# MLDR187 register map
File version: 1.4
MLDR187. Rev2+
CPU: MDR32F02, little endian
Registers are 32-bit, read-write, no defined reset value unless marked. A register's access mark holds for its fields unless they carry their own. Offsets are from the block's base; lines under a group give offsets from that group; [hi:lo] are bit positions; {n}, {i} and the like mark numbered series; 'fields as' and 'values as' point back to an identical list; <NAME> marks a mode.

## Memory map
0x02000000 CLINT size 0x1000 — CLINT description
0x0C000000 PLIC size 0x1000 — PLIC description
0x40000000 SPI1 size 0x1000 — SPI1 description
0x40008000 UART1 size 0x1000 — UART1 description
0x40010000 UART2 size 0x1000 — UART2 description
0x40018000 EEPROM_CNTRL size 0x1000 — EEPROM_CNTRL description
0x40020000 RST_CLK size 0x1000 — RST_CLK description
0x40028000 DMA size 0x1000 — DMA description
0x40030000 I2C size 0x1000 — I2C description
0x40038000 UART3 size 0x1000 — UART3 description
0x40040000 ADC size 0x1000 — ADC description
0x40048000 WWDG size 0x1000 — WWDG description
0x40050000 IWDG size 0x1000 — IWDG description
0x40058000 POWER size 0x1000 — POWER description
0x40060000 BKP size 0x1000 — BKP description
0x40068000 ADCUI size 0x1000 — ADCUI description
0x40070000 TIMER1 size 0x1000 — TIMER1 description
0x40078000 TIMER2 size 0x1000 — TIMER2 description
0x40080000 PORTA size 0x1000 — PORTA description
0x40088000 PORTB size 0x1000 — PORTB description
0x40090000 PORTC size 0x1000 — PORTC description
0x40098000 CRC size 0x1000 — CRC description
0x400A8000 SENSORS size 0x1000 — SENSORS description
0x400B0000 CLK_MEASURE size 0x1000 — CLK_MEASURE description
0x400B8000 RANDOM size 0x1000 — RANDOM description
0x400C0000 ISO7816 size 0x1000 — ISO7816 description
0x400C8000 SPI2 size 0x1000 — SPI2 description
0x400D0000 SPI3 size 0x1000 — SPI3 description
0x400D8000 TIMER3 size 0x1000 — TIMER3 description
0x400E0000 TIMER4 size 0x1000 — TIMER4 description
0x400E8000 UART4 size 0x1000 — UART4 description
0x400F0000 PORTD size 0x1000 — PORTD description
0x60004000 LBLOCK size 0x1000 — LBLOCK description
{0x60008000+0x4000*n} SBLOCK{n} size 0x1000 (n=0..7) — SBLOCK{n} description
0x60028000 PBYTE size 0x1000 — PBYTE description
0x6002C000 P_BIT0 size 0x1000 — P_BIT0 description
0x60030000 P_BIT1 size 0x1000 — P_BIT1 description
0x60034000 P_BIT2 size 0x1000 — P_BIT2 description
0x60038000 P_BIT3 size 0x1000 — P_BIT3 description
0x70010000 OTP size 0x1000 — OTP description

## CLINT — CLINT description
Base 0x02000000
0x00 CTMSIP — CTMSIP description
0x4000 CTMTIMECMP 64-bit — CTMTIMECMP description
0xBFF8 CTMTIME 64-bit — CTMTIME description

## PLIC — PLIC description
Base 0x0C000000
{0x0+4i} PLPRI{i} (i=1..31) — PLPRI{i} description
  [2:0] PRI — PRI description
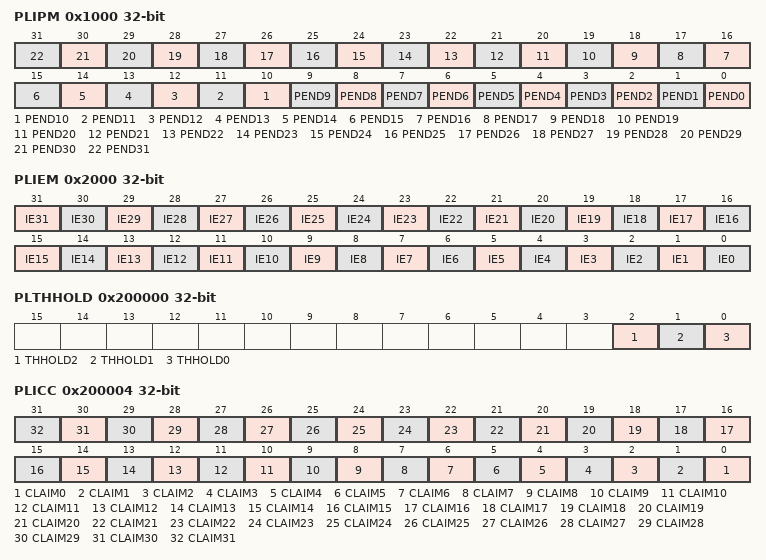
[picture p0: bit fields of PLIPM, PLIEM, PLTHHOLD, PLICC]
0x1000 PLIPM ro — PLIPM description
  [n] PEND{n} (n=0..31) — PEND{n} description
0x2000 PLIEM — PLIEM description
  [n] IE{n} (n=1..31) — IE{n} description
  [0] IE0 ro — IE0 description
0x200000 PLTHHOLD — PLTHHOLD description
  [2] THHOLD2 — THHOLD2 description
  [1] THHOLD1 — THHOLD1 description
  [0] THHOLD0 — THHOLD0 description
0x200004 PLICC — PLICC description
  [n] CLAIM{n} (n=0..31) — CLAIM{n} description

## DMA — DMA description
Base 0x40028000
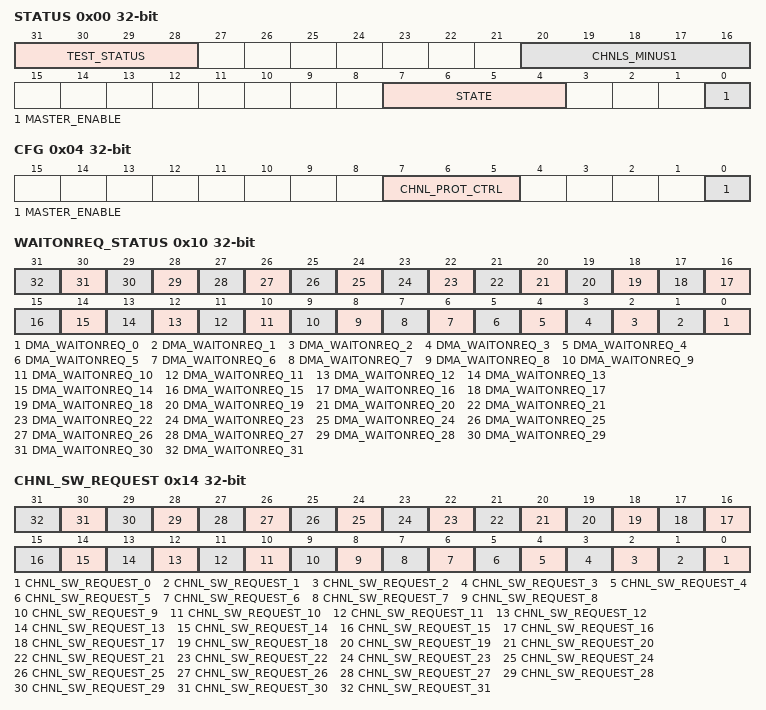
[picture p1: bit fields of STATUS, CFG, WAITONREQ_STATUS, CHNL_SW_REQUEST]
0x00 STATUS — STATUS description
  [31:28] TEST_STATUS ro — TEST_STATUS description
  [20:16] CHNLS_MINUS1 ro — CHNLS_MINUS1 description
  [7:4] STATE ro — STATE description
  [0] MASTER_ENABLE ro — MASTER_ENABLE description
0x04 CFG — CFG description
  [7:5] CHNL_PROT_CTRL wo — CHNL_PROT_CTRL description
  [0] MASTER_ENABLE wo — MASTER_ENABLE description
0x08 CTRL_BASE_PTR — CTRL_BASE_PTR description
  [31:10] CTRL_BASE_PTR
0x0C ALT_CTRL_BASE_PTR ro — ALT_CTRL_BASE_PTR description
0x10 WAITONREQ_STATUS ro — WAITONREQ_STATUS description
  [n] DMA_WAITONREQ_{n} (n=0..31) — DMA_WAITONREQ_{n} description
0x14 CHNL_SW_REQUEST wo — CHNL_SW_REQUEST description
  [n] CHNL_SW_REQUEST_{n} (n=0..31) — CHNL_SW_REQUEST_{n} description
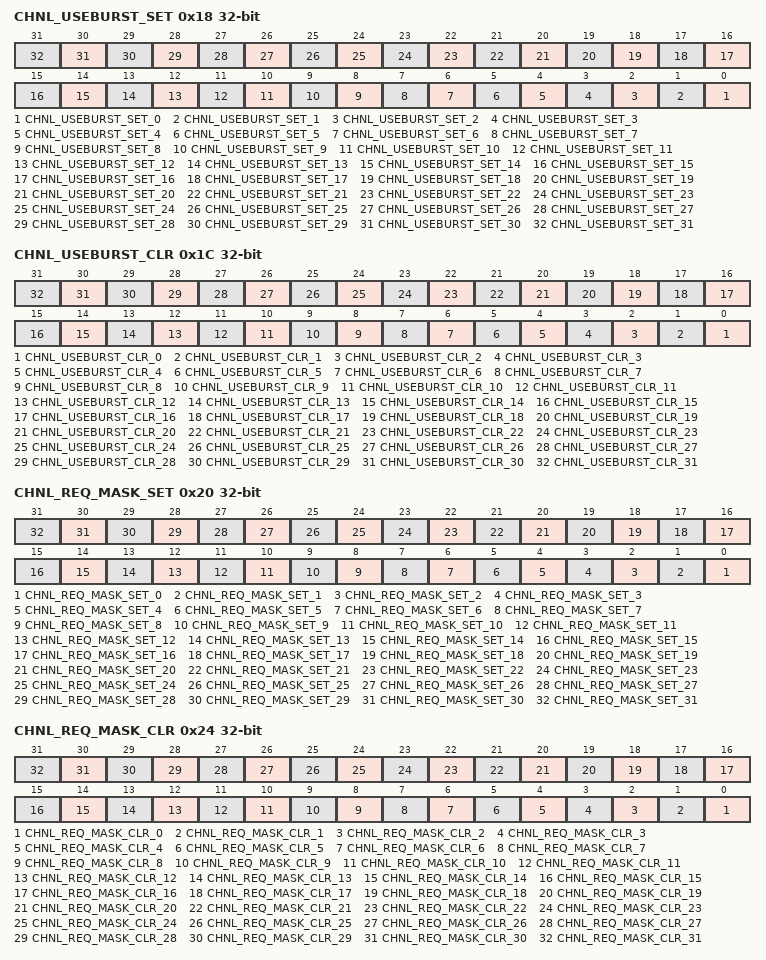
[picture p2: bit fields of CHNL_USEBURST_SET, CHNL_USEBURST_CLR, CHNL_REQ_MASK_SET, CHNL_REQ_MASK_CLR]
0x18 CHNL_USEBURST_SET — CHNL_USEBURST_SET description
  [n] CHNL_USEBURST_SET_{n} (n=0..31) — CHNL_USEBURST_SET_{n} description
0x1C CHNL_USEBURST_CLR wo — CHNL_USEBURST_CLR description
  [n] CHNL_USEBURST_CLR_{n} (n=0..31) — CHNL_USEBURST_CLR_{n} description
0x20 CHNL_REQ_MASK_SET — CHNL_REQ_MASK_SET description
  [n] CHNL_REQ_MASK_SET_{n} (n=0..31) — CHNL_REQ_MASK_SET_{n} description
0x24 CHNL_REQ_MASK_CLR wo — CHNL_REQ_MASK_CLR description
  [n] CHNL_REQ_MASK_CLR_{n} (n=0..31) — CHNL_REQ_MASK_CLR_{n} description
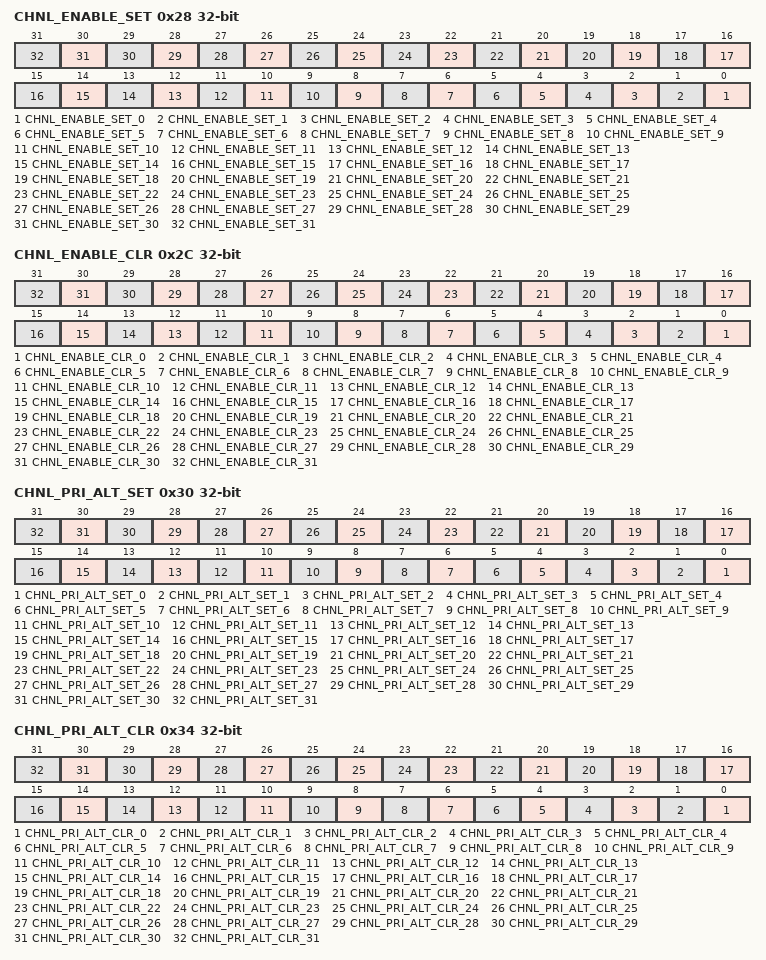
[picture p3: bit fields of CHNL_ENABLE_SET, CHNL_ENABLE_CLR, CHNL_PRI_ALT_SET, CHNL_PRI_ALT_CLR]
0x28 CHNL_ENABLE_SET — CHNL_ENABLE_SET description
  [n] CHNL_ENABLE_SET_{n} (n=0..31) — CHNL_ENABLE_SET_{n} description
0x2C CHNL_ENABLE_CLR wo — CHNL_ENABLE_CLR description
  [n] CHNL_ENABLE_CLR_{n} (n=0..31) — CHNL_ENABLE_CLR_{n} description
0x30 CHNL_PRI_ALT_SET — CHNL_PRI_ALT_SET description
  [n] CHNL_PRI_ALT_SET_{n} (n=0..31) — CHNL_PRI_ALT_SET_{n} description
0x34 CHNL_PRI_ALT_CLR wo — CHNL_PRI_ALT_CLR description
  [n] CHNL_PRI_ALT_CLR_{n} (n=0..31) — CHNL_PRI_ALT_CLR_{n} description
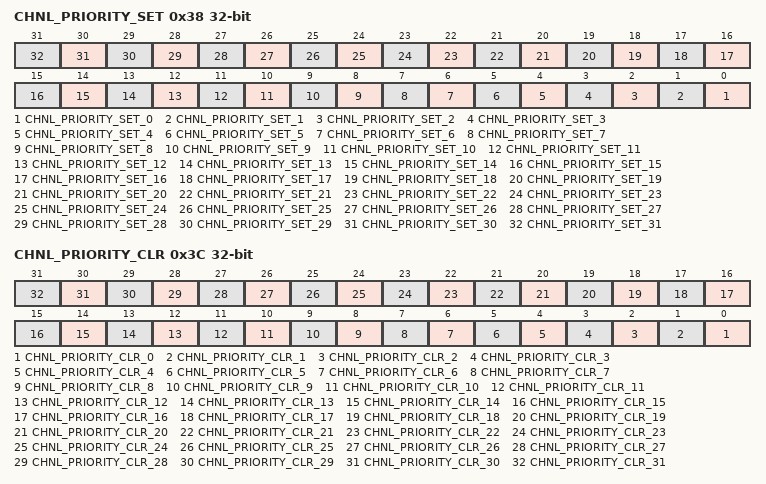
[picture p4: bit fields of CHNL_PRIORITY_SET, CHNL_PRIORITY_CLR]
0x38 CHNL_PRIORITY_SET — CHNL_PRIORITY_SET description
  [n] CHNL_PRIORITY_SET_{n} (n=0..31) — CHNL_PRIORITY_SET_{n} description
0x3C CHNL_PRIORITY_CLR wo — CHNL_PRIORITY_CLR description
  [n] CHNL_PRIORITY_CLR_{n} (n=0..31) — CHNL_PRIORITY_CLR_{n} description
0x4C ERR_CLR — ERR_CLR description
  [0] ERR_CLR
